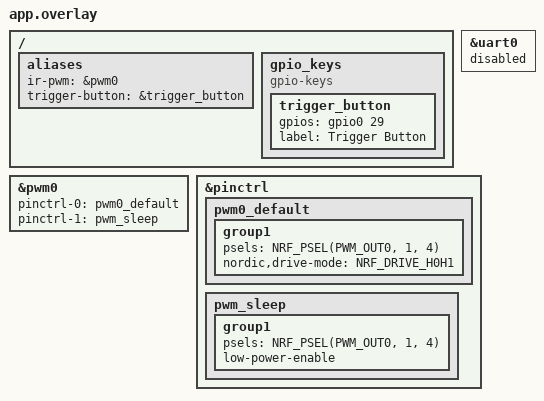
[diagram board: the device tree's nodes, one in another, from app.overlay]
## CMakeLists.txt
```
# SPDX-License-Identifier: Apache-2.0
cmake_minimum_required(VERSION 3.20.0)

set(DTC_OVERLAY_FILE app.overlay)

find_package(Zephyr REQUIRED HINTS $ENV{ZEPHYR_BASE})
project(emitter)

add_subdirectory(../common common)

target_sources(app PRIVATE
    src/main.c
    src/ble_phone.c
    src/ble_vest.c
    src/game_state.c
    src/mesh.c
)

target_link_libraries(app PUBLIC common)
target_include_directories(app PRIVATE src)
```

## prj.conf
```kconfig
CONFIG_NEWLIB_LIBC=y

# --- Stack and Heap ---
CONFIG_MAIN_STACK_SIZE=4096
CONFIG_SYSTEM_WORKQUEUE_STACK_SIZE=4096

# --- Logging ---
CONFIG_LOG=y
CONFIG_LOG_DEFAULT_LEVEL=3
CONFIG_USE_SEGGER_RTT=y
CONFIG_LOG_BACKEND_RTT=y

# --- Bluetooth Low Energy ---
CONFIG_BT=y
CONFIG_BT_PERIPHERAL=y
CONFIG_BT_CENTRAL=y
CONFIG_BT_GATT_CLIENT=y
CONFIG_BT_DEVICE_NAME_DYNAMIC=y
CONFIG_BT_DEVICE_NAME="LT-E-0000"
CONFIG_BT_MAX_CONN=3

# --- ATT MTU ---
# The phone's CMD_BROADCAST_GAME_CFG payload (game header + teams + roster +
# emitter config + boundary) is ~45-200 bytes. The default 23-byte ATT MTU caps
# a single write at 20 bytes, which would force iOS into an ATT Long Write that
# this server rejects (CONFIG_BT_ATT_PREPARE_COUNT defaults to 0), so the write
# silently fails and the game never starts. Bump the MTU so the whole config
# lands in one write. DLE max lets it travel without LL fragmentation.
CONFIG_BT_L2CAP_TX_MTU=247
CONFIG_BT_BUF_ACL_TX_SIZE=251
CONFIG_BT_BUF_ACL_RX_SIZE=251
CONFIG_BT_CTLR_DATA_LENGTH_MAX=251

# --- Hardware Drivers ---
CONFIG_GPIO=y
CONFIG_PWM=y

# --- Settings Subsystem (NVS) ---
CONFIG_SETTINGS=y
CONFIG_FLASH=y
CONFIG_FLASH_PAGE_LAYOUT=y
CONFIG_FLASH_MAP=y
CONFIG_NVS=y
CONFIG_SETTINGS_NVS=y

# --- Coded PHY & Extended Adv ---
CONFIG_BT_OBSERVER=y
CONFIG_BT_BROADCASTER=y
CONFIG_BT_EXT_ADV=y
CONFIG_BT_EXT_ADV_MAX_ADV_SET=3
CONFIG_BT_CTLR_ADV_EXT=y
CONFIG_BT_CTLR_PHY_CODED=y
CONFIG_BT_USER_PHY_UPDATE=y

# --- TX Power (max for mesh range) ---
CONFIG_BT_CTLR_TX_PWR_PLUS_8=y

# --- Entropy for random numbers ---
CONFIG_ENTROPY_GENERATOR=y
CONFIG_TEST_RANDOM_GENERATOR=n
CONFIG_BT_GATT_AUTO_DISCOVER_CCC=y
```

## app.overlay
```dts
/ {
    aliases {
        ir-pwm = &pwm0;
        trigger-button = &trigger_button;
    };

    gpio_keys {
        compatible = "gpio-keys";
        trigger_button: trigger_button {
            /* Trigger switch is on P0.29, normally-closed, wired between
             * pin and GND. With the NC closed at idle, the switch shorts
             * the pin to GND (overrides the internal pull-up). Pressing
             * the trigger opens the NC contact, the pull-up takes the
             * pin HIGH, which reads as "active" per GPIO_ACTIVE_HIGH.
             *
             * Symptom that pinpointed this wiring: with ACTIVE_HIGH +
             * PULL_DOWN, no fires happen because pressing doesn't pull
             * the pin HIGH (NC opens, but pull-down still wins). With
             * ACTIVE_LOW + PULL_UP, fires happen at idle because the
             * NC short reads as "active". The combo here is the only
             * one that lines up.
             *
             * The 20 ms ISR debounce in trigger_pressed_cb handles the
             * release-bounce that previously caused double-fires under
             * this same polarity + pull combo.
             */
            gpios = <&gpio0 29 (GPIO_ACTIVE_HIGH | GPIO_PULL_UP)>;
            label = "Trigger Button";
        };
    };
};

/*
 * Disable uart0 to free up its pins (like P0.20) for other uses.
 * This is safe because we are using the USB serial backend for logs.
 */
&uart0 {
    status = "disabled";
};

&pwm0 {
    status = "okay";
    pinctrl-0 = <&pwm0_default>;
    pinctrl-1 = <&pwm_sleep>;
    pinctrl-names = "default", "sleep";
};

&pinctrl {
    pwm0_default: pwm0_default {
        group1 {
            /* IR LED on P1.04. H0H1 high drive (~5 mA, vs ~0.5 mA standard)
             * so the pin can source enough current for a direct-driven IR LED
             * or hard-saturate the switching transistor.
             */
            psels = <NRF_PSEL(PWM_OUT0, 1, 4)>;
            nordic,drive-mode = <NRF_DRIVE_H0H1>;
        };
    };

    pwm_sleep: pwm_sleep {
        group1 {
            psels = <NRF_PSEL(PWM_OUT0, 1, 4)>;
            low-power-enable;
        };
    };
};
```

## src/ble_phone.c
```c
#include "ble_phone.h"
#include "protocol.h"
#include <zephyr/bluetooth/gatt.h>
#include <zephyr/bluetooth/uuid.h>
#include <zephyr/logging/log.h>
#include <stdarg.h>
#include <stdio.h>
#include <string.h>

LOG_MODULE_REGISTER(ble_phone, LOG_LEVEL_INF);

/* Emitter Service: e4b50001-c812-4d2b-b6d0-456789abcdef */
#define BT_UUID_EMITTER_SVC_VAL BT_UUID_128_ENCODE(0xe4b50001, 0xc812, 0x4d2b, 0xb6d0, 0x456789abcdef)
#define BT_UUID_EMITTER_RX_VAL  BT_UUID_128_ENCODE(0xe4b50002, 0xc812, 0x4d2b, 0xb6d0, 0x456789abcdef)
#define BT_UUID_EMITTER_TX_VAL  BT_UUID_128_ENCODE(0xe4b50003, 0xc812, 0x4d2b, 0xb6d0, 0x456789abcdef)

#define BT_UUID_EMITTER_SVC BT_UUID_DECLARE_128(BT_UUID_EMITTER_SVC_VAL)
#define BT_UUID_EMITTER_RX  BT_UUID_DECLARE_128(BT_UUID_EMITTER_RX_VAL)
#define BT_UUID_EMITTER_TX  BT_UUID_DECLARE_128(BT_UUID_EMITTER_TX_VAL)

static ble_phone_rx_cb_t app_rx_cb;

/* Tracked separately from the caller's `phone_conn` so the logging path
 * doesn't have to thread a connection pointer through every module.
 * Set/cleared by main.c via ble_phone_log_set_conn in the BLE
 * connected/disconnected callbacks.
 */
static struct bt_conn *log_conn;

static ssize_t on_rx_write(struct bt_conn *conn, const struct bt_gatt_attr *attr,
                           const void *buf, uint16_t len, uint16_t offset, uint8_t flags)
{
    if (len > 0 && app_rx_cb) {
        app_rx_cb((const uint8_t *)buf, len);
    }
    return len;
}

BT_GATT_SERVICE_DEFINE(emitter_phone_svc,
    BT_GATT_PRIMARY_SERVICE(BT_UUID_EMITTER_SVC),
    BT_GATT_CHARACTERISTIC(BT_UUID_EMITTER_TX,
                           BT_GATT_CHRC_NOTIFY,
                           BT_GATT_PERM_NONE,
                           NULL, NULL, NULL),
    BT_GATT_CCC(NULL, BT_GATT_PERM_READ | BT_GATT_PERM_WRITE),
    BT_GATT_CHARACTERISTIC(BT_UUID_EMITTER_RX,
                           BT_GATT_CHRC_WRITE | BT_GATT_CHRC_WRITE_WITHOUT_RESP,
                           BT_GATT_PERM_WRITE,
                           NULL, on_rx_write, NULL),
);

void ble_phone_init(ble_phone_rx_cb_t rx_cb)
{
    app_rx_cb = rx_cb;
}

void ble_phone_notify(struct bt_conn *conn, const uint8_t *data, uint16_t len)
{
    if (!conn) {
        return;
    }
    int err = bt_gatt_notify(conn, &emitter_phone_svc.attrs[2], data, len);
    if (err) {
        LOG_WRN("Phone notify failed (err %d)", err);
    }
}

void ble_phone_log_set_conn(struct bt_conn *conn)
{
    log_conn = conn;
}

void ble_phone_log(uint8_t severity, const char *fmt, ...)
{
    if (!log_conn) {
        return;
    }

    /* notify_buf layout: [opcode][severity][text...] — text is NOT
     * NUL-terminated; the receiver uses the BLE notify length to know
     * where it ends.
     */
    uint8_t notify_buf[152];
    notify_buf[0] = RSP_LOG;
    notify_buf[1] = severity;

    va_list ap;
    va_start(ap, fmt);
    int n = vsnprintf((char *)&notify_buf[2], sizeof(notify_buf) - 2, fmt, ap);
    va_end(ap);

    if (n < 0) {
        return;
    }
    size_t text_len = (size_t)n;
    if (text_len > sizeof(notify_buf) - 2) {
        text_len = sizeof(notify_buf) - 2;  /* vsnprintf truncated */
    }
    size_t total = 2 + text_len;

    /* Notification payload is bounded by the current ATT MTU minus the
     * 3-byte ATT_HANDLE_VALUE_NTF header. iOS auto-negotiates ~185 byte
     * MTU shortly after connect but the exchange takes a moment — if a
     * log line fires before MTU is up, bt_gatt_notify returns -EMSGSIZE
     * and the entire line is silently lost. Trim to whatever MTU
     * actually is right now (worst case 23 → 20 byte payloads).
     */
    uint16_t mtu = bt_gatt_get_mtu(log_conn);
    if (mtu < 5) {
        return;  /* shouldn't happen — bail rather than write a negative size */
    }
    size_t max_payload = (size_t)mtu - 3;
    if (total > max_payload) {
        total = max_payload;
    }

    /* bt_gatt_notify is non-blocking and returns -ENOMEM if the host's
     * TX queue is full; we drop the log line in that case rather than
     * blocking the caller (which may be on the BT host thread itself).
     * Log failures so they're at least visible in RTT when attached.
     */
    int err = bt_gatt_notify(log_conn, &emitter_phone_svc.attrs[2],
                             notify_buf, total);
    if (err) {
        LOG_WRN("RSP_LOG notify failed (err %d, mtu=%u, total=%u)",
                err, mtu, (unsigned)total);
    }
}
```

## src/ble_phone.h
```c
#ifndef BLE_PHONE_H
#define BLE_PHONE_H

#include <zephyr/bluetooth/bluetooth.h>
#include <zephyr/bluetooth/conn.h>
#include <zephyr/logging/log.h>
#include <stdint.h>

typedef void (*ble_phone_rx_cb_t)(const uint8_t *data, uint16_t len);

void ble_phone_init(ble_phone_rx_cb_t rx_cb);
void ble_phone_notify(struct bt_conn *conn, const uint8_t *data, uint16_t len);

/* ===== Log relay to phone =====
 *
 * Forwards short log lines to the phone over the existing emitter
 * connection as RSP_LOG notifications. Useful when the emitter is on
 * battery and SWD isn't accessible: the iOS app's log viewer surfaces
 * what the RTT terminal would normally show.
 *
 * Severity values: 0=DBG 1=INF 2=WRN 3=ERR. Lines longer than the
 * negotiated ATT MTU are truncated (~150 bytes typically).
 *
 * Use PLOG_INF/PLOG_WRN/PLOG_ERR macros: they log to the Zephyr backend
 * (RTT) AND relay to the phone in one call, so there's a single source
 * of truth for the message text.
 */
void ble_phone_log_set_conn(struct bt_conn *conn);
void ble_phone_log(uint8_t severity, const char *fmt, ...);

#define PLOG_INF(fmt, ...) do { \
    LOG_INF(fmt, ##__VA_ARGS__); \
    ble_phone_log(1, fmt, ##__VA_ARGS__); \
} while (0)

#define PLOG_WRN(fmt, ...) do { \
    LOG_WRN(fmt, ##__VA_ARGS__); \
    ble_phone_log(2, fmt, ##__VA_ARGS__); \
} while (0)

#define PLOG_ERR(fmt, ...) do { \
    LOG_ERR(fmt, ##__VA_ARGS__); \
    ble_phone_log(3, fmt, ##__VA_ARGS__); \
} while (0)

#endif
```

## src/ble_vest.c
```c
#include "ble_vest.h"
#include "ble_phone.h"
#include "protocol.h"
#include "mesh.h"
#include <zephyr/kernel.h>
#include <zephyr/bluetooth/gatt.h>
#include <zephyr/bluetooth/uuid.h>
#include <zephyr/bluetooth/hci.h>
#include <zephyr/sys/byteorder.h>
#include <zephyr/logging/log.h>
#include <string.h>

LOG_MODULE_REGISTER(ble_vest, LOG_LEVEL_INF);

/* Vest Service UUIDs */
#define BT_UUID_VEST_SVC_VAL    BT_UUID_128_ENCODE(0xa7d80001, 0x1234, 0x5678, 0xabcd, 0x0123456789ab)
#define BT_UUID_VEST_HIT_TX_VAL BT_UUID_128_ENCODE(0xa7d80002, 0x1234, 0x5678, 0xabcd, 0x0123456789ab)
#define BT_UUID_VEST_CMD_RX_VAL BT_UUID_128_ENCODE(0xa7d80003, 0x1234, 0x5678, 0xabcd, 0x0123456789ab)

static struct bt_uuid_128 vest_svc_uuid    = BT_UUID_INIT_128(BT_UUID_VEST_SVC_VAL);
static struct bt_uuid_128 vest_hit_tx_uuid = BT_UUID_INIT_128(BT_UUID_VEST_HIT_TX_VAL);
static struct bt_uuid_128 vest_cmd_rx_uuid = BT_UUID_INIT_128(BT_UUID_VEST_CMD_RX_VAL);

/* State */
static struct bt_conn *vest_conn;
static uint16_t cmd_rx_handle;
static ble_vest_hit_cb_t hit_cb;
static ble_vest_connected_cb_t connected_cb;
static ble_vest_disconnected_cb_t disconnected_cb;
static ble_vest_ready_cb_t ready_cb;
static uint8_t vest_mac[6];
static bool has_vest_mac;

/* GATT discovery state machine */
enum discover_stage {
    DISC_SERVICE,
    DISC_CHAR,
    DISC_CCC,
    DISC_DONE,
};
static enum discover_stage disc_stage;
static struct bt_gatt_discover_params discover_params;
static struct bt_gatt_subscribe_params subscribe_params;
static uint16_t svc_start_handle;
static uint16_t svc_end_handle;
static uint16_t hit_tx_value_handle;

/* Deferred firing of ready_cb — runs on system workqueue so the callback
 * (which typically issues another GATT write) doesn't execute inside the
 * BT host thread's discovery callback.
 */
static struct k_work ready_cb_work;

static void ready_cb_handler(struct k_work *work)
{
    if (ready_cb) {
        ready_cb();
    }
}

/* Forward declarations */
static uint8_t gatt_discover_cb(struct bt_conn *conn,
                                const struct bt_gatt_attr *attr,
                                struct bt_gatt_discover_params *params);

static uint8_t hit_notify_cb(struct bt_conn *conn,
                             struct bt_gatt_subscribe_params *params,
                             const void *data, uint16_t length)
{
    if (!data || length < VEST_HIT_PAYLOAD_SIZE) {
        return BT_GATT_ITER_CONTINUE;
    }

    const uint8_t *d = data;
    uint16_t packet_id = sys_get_le16(&d[0]);
    uint8_t shooter_id = d[2];
    uint8_t weapon_id  = d[3];
    uint8_t team_id    = d[4];

    PLOG_INF("Vest hit RX: pkt=0x%04x shooter=%d weapon=%d team=%d",
             packet_id, shooter_id, weapon_id, team_id);

    if (hit_cb) {
        hit_cb(packet_id, shooter_id, weapon_id, team_id);
    }
    return BT_GATT_ITER_CONTINUE;
}

static void start_gatt_discovery(struct bt_conn *conn)
{
    disc_stage = DISC_SERVICE;
    discover_params.uuid = &vest_svc_uuid.uuid;
    discover_params.func = gatt_discover_cb;
    discover_params.start_handle = BT_ATT_FIRST_ATTRIBUTE_HANDLE;
    discover_params.end_handle = BT_ATT_LAST_ATTRIBUTE_HANDLE;
    discover_params.type = BT_GATT_DISCOVER_PRIMARY;

    int err = bt_gatt_discover(conn, &discover_params);
    if (err) {
        LOG_ERR("GATT discovery start failed (err %d)", err);
    }
}

static uint8_t gatt_discover_cb(struct bt_conn *conn,
                                const struct bt_gatt_attr *attr,
                                struct bt_gatt_discover_params *params)
{
    if (!attr) {
        if (disc_stage == DISC_SERVICE) {
            PLOG_ERR("Vest service not found");
        }
        return BT_GATT_ITER_STOP;
    }

    switch (disc_stage) {
    case DISC_SERVICE: {
        struct bt_gatt_service_val *svc = attr->user_data;
        svc_start_handle = attr->handle + 1;
        svc_end_handle = svc->end_handle;
        LOG_INF("Vest service found: handles %d-%d", svc_start_handle, svc_end_handle);

        disc_stage = DISC_CHAR;
        discover_params.uuid = NULL;
        discover_params.start_handle = svc_start_handle;
        discover_params.end_handle = svc_end_handle;
        discover_params.type = BT_GATT_DISCOVER_CHARACTERISTIC;

        int err = bt_gatt_discover(conn, &discover_params);
        if (err) {
            LOG_ERR("Char discovery failed (err %d)", err);
        }
        return BT_GATT_ITER_STOP;
    }

    case DISC_CHAR: {
        struct bt_gatt_chrc *chrc = attr->user_data;
        if (!bt_uuid_cmp(chrc->uuid, &vest_hit_tx_uuid.uuid)) {
            hit_tx_value_handle = chrc->value_handle;
            LOG_INF("Hit TX char found: handle %d", hit_tx_value_handle);
        } else if (!bt_uuid_cmp(chrc->uuid, &vest_cmd_rx_uuid.uuid)) {
            cmd_rx_handle = chrc->value_handle;
            LOG_INF("Cmd RX char found: handle %d", cmd_rx_handle);
        }

        if (hit_tx_value_handle && cmd_rx_handle) {
            disc_stage = DISC_CCC;
            subscribe_params.notify = hit_notify_cb;
            subscribe_params.value_handle = hit_tx_value_handle;
            subscribe_params.ccc_handle = 0;
            subscribe_params.end_handle = svc_end_handle;
            subscribe_params.disc_params = &discover_params;
            subscribe_params.value = BT_GATT_CCC_NOTIFY;

            int err = bt_gatt_subscribe(conn, &subscribe_params);
            if (err && err != -EALREADY) {
                PLOG_ERR("Subscribe failed (err %d)", err);
            } else {
                PLOG_INF("Subscribed to vest Hit TX");
                disc_stage = DISC_DONE;
                k_work_submit(&ready_cb_work);
            }
            return BT_GATT_ITER_STOP;
        }
        return BT_GATT_ITER_CONTINUE;
    }

    default:
        return BT_GATT_ITER_STOP;
    }
}

static void vest_conn_connected(struct bt_conn *conn, uint8_t err)
{
    /* Bail early if this isn't our pending vest connection — the connected
     * callback also fires for phone connections, and an err here for the
     * phone must not wipe out a separately-tracked vest connection.
     */
    if (conn != vest_conn) {
        return;
    }

    if (err) {
        PLOG_ERR("Vest connection failed (err %d)", err);
        bt_conn_unref(vest_conn);
        vest_conn = NULL;
        mesh_start_scanner();
        return;
    }

    const bt_addr_le_t *addr = bt_conn_get_dst(conn);
    if (!addr) {
        return;
    }

    char addr_str[BT_ADDR_LE_STR_LEN];
    bt_addr_le_to_str(addr, addr_str, sizeof(addr_str));
    LOG_INF("Vest connected: %s", addr_str);

    memcpy(vest_mac, addr->a.val, 6);
    has_vest_mac = true;

    cmd_rx_handle = 0;
    hit_tx_value_handle = 0;
    start_gatt_discovery(conn);

    /* Deliberately do NOT restart the mesh scanner here. Scanning during
     * GATT discovery time-slices the radio against both the new vest
     * connection's traffic and the existing phone connection — on a
     * Pro Micro that's enough to make supervision packets to the phone
     * slip and iOS drops the link mid-pairing. The scanner gets
     * restarted from on_vest_gatt_ready once discovery has completed.
     */

    if (connected_cb) {
        connected_cb(vest_mac);
    }
}

static void vest_conn_disconnected(struct bt_conn *conn, uint8_t reason)
{
    if (conn == vest_conn) {
        LOG_INF("Vest disconnected (reason %d)", reason);
        bt_conn_unref(vest_conn);
        vest_conn = NULL;
        cmd_rx_handle = 0;
        hit_tx_value_handle = 0;

        mesh_start_scanner();

        if (disconnected_cb) {
            disconnected_cb(reason);
        }
    }
}

BT_CONN_CB_DEFINE(vest_conn_cbs) = {
    .connected = vest_conn_connected,
    .disconnected = vest_conn_disconnected,
};

/* ===== Vest Scan (1M PHY for vest pairing/reconnect) ===== */

void ble_vest_stop_scan(void)
{
    int err = bt_le_scan_stop();
    if (err && err != -EALREADY) {
        LOG_WRN("Stop scan failed (err %d)", err);
    }
}

static void vest_scan_connect(const bt_addr_le_t *addr)
{
    if (vest_conn) {
        mesh_start_scanner();
        return;
    }

    struct bt_le_conn_param conn_param = BT_LE_CONN_PARAM_INIT(
        BT_GAP_INIT_CONN_INT_MIN, BT_GAP_INIT_CONN_INT_MAX, 0, 400);

    struct bt_conn *conn;
    int err = bt_conn_le_create(addr, BT_CONN_LE_CREATE_CONN,
                                &conn_param, &conn);
    if (err) {
        LOG_ERR("Vest connect failed (err %d)", err);
        mesh_start_scanner();
        return;
    }
    vest_conn = conn;
    LOG_INF("Connecting to vest...");
}

void ble_vest_init(ble_vest_hit_cb_t hit_callback,
                   ble_vest_connected_cb_t conn_cb,
                   ble_vest_disconnected_cb_t disc_cb,
                   ble_vest_ready_cb_t rdy_cb)
{
    hit_cb = hit_callback;
    connected_cb = conn_cb;
    disconnected_cb = disc_cb;
    ready_cb = rdy_cb;
    k_work_init(&ready_cb_work, ready_cb_handler);
}

void ble_vest_on_scan_result(const bt_addr_le_t *addr, int8_t rssi,
                             struct net_buf_simple *buf)
{
    if (vest_conn) {
        return;
    }

    /* Look for vest name prefix "LT-V-" in the advertisement */
    if (buf->len >= 2) {
        uint8_t *d = buf->data;
        uint16_t pos = 0;
        while (pos + 1 < buf->len) {
            uint8_t ad_len = d[pos];
            if (ad_len == 0 || pos + 1 + ad_len > buf->len) {
                break;
            }
            uint8_t ad_type = d[pos + 1];
            if ((ad_type == BT_DATA_NAME_COMPLETE || ad_type == BT_DATA_NAME_SHORTENED) &&
                ad_len >= 6) {
                const char *name = (const char *)&d[pos + 2];
                if (name[0] == 'L' && name[1] == 'T' && name[2] == '-' &&
                    name[3] == 'V' && name[4] == '-') {
                    LOG_INF("Found vest: RSSI=%d", rssi);
                    ble_vest_stop_scan();
                    vest_scan_connect(addr);
                    return;
                }
            }
            pos += ad_len + 1;
        }
    }
}

/* ===== Commands to Vest ===== */

static int vest_write(const uint8_t *data, uint16_t len)
{
    if (!vest_conn || cmd_rx_handle == 0) {
        return -ENOTCONN;
    }
    return bt_gatt_write_without_response(vest_conn, cmd_rx_handle, data, len, false);
}

int ble_vest_send_hit_ack(uint16_t packet_id)
{
    uint8_t buf[3];
    buf[0] = VEST_CMD_HIT_ACK;
    sys_put_le16(packet_id, &buf[1]);
    return vest_write(buf, 3);
}

int ble_vest_send_friendly_list(const uint8_t *player_ids, uint8_t count)
{
    uint8_t buf[2 + MAX_PLAYERS];
    buf[0] = VEST_CMD_FRIENDLY_LIST;
    buf[1] = count;
    if (count > MAX_PLAYERS) count = MAX_PLAYERS;
    memcpy(&buf[2], player_ids, count);
    return vest_write(buf, 2 + count);
}

int ble_vest_send_death(void)
{
    uint8_t buf[1] = { VEST_CMD_DEATH };
    return vest_write(buf, 1);
}

int ble_vest_send_respawn(void)
{
    uint8_t buf[1] = { VEST_CMD_RESPAWN };
    return vest_write(buf, 1);
}

int ble_vest_send_friendly_fire(uint8_t enabled)
{
    uint8_t buf[2] = { VEST_CMD_FRIENDLY_FIRE, enabled };
    return vest_write(buf, 2);
}

int ble_vest_send_unpair(void)
{
    uint8_t buf[1] = { VEST_CMD_UNPAIR };
    return vest_write(buf, 1);
}

bool ble_vest_is_connected(void)
{
    return vest_conn != NULL && cmd_rx_handle != 0;
}

bool ble_vest_link_up(void)
{
    return vest_conn != NULL;
}

void ble_vest_disconnect(void)
{
    if (vest_conn) {
        bt_conn_disconnect(vest_conn, BT_HCI_ERR_REMOTE_USER_TERM_CONN);
    }
}

bool ble_vest_get_active_mac(uint8_t mac_out[6])
{
    if (!vest_conn || !has_vest_mac) {
        return false;
    }
    memcpy(mac_out, vest_mac, 6);
    return true;
}
```

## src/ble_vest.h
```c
#ifndef BLE_VEST_H
#define BLE_VEST_H

#include <zephyr/bluetooth/bluetooth.h>
#include <zephyr/bluetooth/conn.h>
#include <zephyr/net_buf.h>
#include <stdint.h>
#include <stdbool.h>

typedef void (*ble_vest_hit_cb_t)(uint16_t packet_id, uint8_t shooter_id,
                                  uint8_t weapon_id, uint8_t team_id);
typedef void (*ble_vest_connected_cb_t)(const uint8_t *vest_mac);
typedef void (*ble_vest_disconnected_cb_t)(uint8_t reason);
/* Fired once GATT discovery + subscription have completed and the link
 * is fully usable. Used by the emitter to notify the phone via
 * RSP_VEST_PAIRED at the right moment — after the connection is
 * actually ready to carry commands, not the instant BLE links up.
 */
typedef void (*ble_vest_ready_cb_t)(void);

void ble_vest_init(ble_vest_hit_cb_t hit_cb,
                   ble_vest_connected_cb_t connected_cb,
                   ble_vest_disconnected_cb_t disconnected_cb,
                   ble_vest_ready_cb_t ready_cb);

/* Called from main scan callback when a 1M advertisement is received */
void ble_vest_on_scan_result(const bt_addr_le_t *addr, int8_t rssi,
                             struct net_buf_simple *buf);

void ble_vest_stop_scan(void);

int ble_vest_send_hit_ack(uint16_t packet_id);
int ble_vest_send_friendly_list(const uint8_t *player_ids, uint8_t count);
int ble_vest_send_death(void);
int ble_vest_send_respawn(void);
int ble_vest_send_friendly_fire(uint8_t enabled);
int ble_vest_send_unpair(void);

bool ble_vest_is_connected(void);
/* True as soon as the BLE link to the vest is established, even before
 * GATT discovery completes. Used by the pairing-IR transmitter to stop
 * firing once we have a connection — continuing to fire from the
 * cooperative IR workqueue starves the system workqueue / BT host
 * thread and prevents PAIR_CONFIRM from going out.
 */
bool ble_vest_link_up(void);
void ble_vest_disconnect(void);

/* If a vest is currently connected at BLE level, copy its 6-byte MAC into
 * mac_out and return true.
 */
bool ble_vest_get_active_mac(uint8_t mac_out[6]);

#endif
```

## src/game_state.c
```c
#include "game_state.h"
#include <zephyr/kernel.h>
#include <zephyr/logging/log.h>

LOG_MODULE_REGISTER(game_state, LOG_LEVEL_INF);

static struct emitter_config cfg;
static uint8_t  health;
static uint16_t mag_current;
static uint16_t reserve_current;
static bool     alive;
static bool     reloading;
static int64_t  last_shot_ms;
static uint16_t kills;
static uint16_t deaths;

void game_state_init(void)
{
    memset(&cfg, 0, sizeof(cfg));
    health = 0;
    mag_current = 0;
    reserve_current = 0;
    alive = false;
    reloading = false;
    last_shot_ms = 0;
    kills = 0;
    deaths = 0;
}

void game_state_set_config(const struct emitter_config *new_cfg)
{
    cfg = *new_cfg;
    LOG_INF("Config set: dmg=%d mag=%d fire_rate=%dms reload=%dms hp=%d ff=%d",
            cfg.damage, cfg.mag_size, cfg.fire_rate_ms,
            cfg.reload_speed_ms, cfg.max_health, cfg.friendly_fire);
}

const struct emitter_config *game_state_get_config(void)
{
    return &cfg;
}

void game_state_start_game(void)
{
    health = cfg.max_health;
    uint16_t starting_mag = (cfg.initial_total_ammo > cfg.mag_size)
                            ? cfg.mag_size : cfg.initial_total_ammo;
    mag_current = starting_mag;
    reserve_current = cfg.initial_total_ammo - starting_mag;
    alive = true;
    reloading = false;
    last_shot_ms = 0;
    kills = 0;
    deaths = 0;
    LOG_INF("Game started: HP=%d Mag=%d Reserve=%d", health, mag_current, reserve_current);
}

bool game_state_try_fire(int64_t now_ms)
{
    if (!alive || reloading || mag_current == 0) {
        return false;
    }
    if (last_shot_ms > 0 && (now_ms - last_shot_ms) < cfg.fire_rate_ms) {
        return false;
    }
    mag_current--;
    last_shot_ms = now_ms;
    return true;
}

bool game_state_apply_hit(uint8_t damage)
{
    if (!alive) {
        return false;
    }
    if (damage >= health) {
        health = 0;
        alive = false;
        deaths++;
        LOG_INF("DEATH! kills=%d deaths=%d", kills, deaths);
        return true;
    }
    health -= damage;
    LOG_INF("Hit taken: HP=%d", health);
    return false;
}

bool game_state_start_reload(void)
{
    if (reloading) {
        return false;
    }
    if (mag_current == cfg.mag_size) {
        return false;
    }
    if (reserve_current == 0 && mag_current > 0) {
        return false;
    }
    reloading = true;
    LOG_INF("Reloading... (%dms)", cfg.reload_speed_ms);
    return true;
}

void game_state_complete_reload(void)
{
    uint16_t needed = cfg.mag_size - mag_current;
    uint16_t transfer = (reserve_current >= needed) ? needed : reserve_current;
    mag_current += transfer;
    reserve_current -= transfer;
    reloading = false;
    LOG_INF("Reload done: Mag=%d Reserve=%d", mag_current, reserve_current);
}

void game_state_respawn(void)
{
    health = cfg.max_health;
    uint16_t starting_mag = (cfg.initial_total_ammo > cfg.mag_size)
                            ? cfg.mag_size : cfg.initial_total_ammo;
    mag_current = starting_mag;
    reserve_current = cfg.initial_total_ammo - starting_mag;
    alive = true;
    reloading = false;
    LOG_INF("Respawned: HP=%d Mag=%d Reserve=%d", health, mag_current, reserve_current);
}

void game_state_add_ammo(uint16_t amount)
{
    reserve_current += amount;
    LOG_INF("Ammo added: +%d, Reserve=%d", amount, reserve_current);
}

void game_state_add_kill(void)
{
    kills++;
}

uint8_t  game_state_get_health(void)       { return health; }
uint16_t game_state_get_mag_ammo(void)     { return mag_current; }
uint16_t game_state_get_reserve_ammo(void) { return reserve_current; }
bool     game_state_is_alive(void)         { return alive; }
bool     game_state_is_reloading(void)     { return reloading; }
uint16_t game_state_get_kills(void)        { return kills; }
uint16_t game_state_get_deaths(void)       { return deaths; }
```

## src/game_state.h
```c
#ifndef GAME_STATE_H
#define GAME_STATE_H

#include "protocol.h"
#include <stdbool.h>

void game_state_init(void);
void game_state_set_config(const struct emitter_config *cfg);
const struct emitter_config *game_state_get_config(void);

void game_state_start_game(void);
bool game_state_try_fire(int64_t now_ms);
bool game_state_apply_hit(uint8_t damage);
bool game_state_start_reload(void);
void game_state_complete_reload(void);
void game_state_respawn(void);
void game_state_add_ammo(uint16_t amount);
void game_state_add_kill(void);

uint8_t  game_state_get_health(void);
uint16_t game_state_get_mag_ammo(void);
uint16_t game_state_get_reserve_ammo(void);
bool     game_state_is_alive(void);
bool     game_state_is_reloading(void);
uint16_t game_state_get_kills(void);
uint16_t game_state_get_deaths(void);

#endif
```

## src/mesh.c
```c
#include "mesh.h"
#include "ble_phone.h"
#include <zephyr/kernel.h>
#include <zephyr/random/random.h>
#include <zephyr/sys/byteorder.h>
#include <zephyr/logging/log.h>
#include <stdlib.h>
#include <string.h>

LOG_MODULE_REGISTER(mesh, LOG_LEVEL_INF);

/* ===== State ===== */
static uint8_t local_player_id;
static uint8_t local_team_id;
static struct bt_conn *phone_conn;
static uint16_t seq_counter;
static mesh_game_start_cb_t game_start_cb;

/* ===== Coded PHY Advertising Set ===== */
static struct bt_le_ext_adv *coded_adv_set;
static struct k_work_delayable stop_adv_work;
static struct k_work tx_pump_work;
static atomic_t is_broadcasting = ATOMIC_INIT(0);

/* ===== TX Queue (multi-context callers serialized into one BLE op stream) =====
 * Callers come from system workqueue (periodic timers), BT host thread
 * (on_vest_hit -> mesh_broadcast_hit_event), and the GATT write handler.
 * Without queueing, overlapping broadcasts fail with -EBUSY and are lost.
 */
#define MESH_TX_QUEUE_SIZE 4
struct mesh_tx_slot {
    uint8_t  buf[256];
    uint16_t len;
};
static struct mesh_tx_slot tx_queue[MESH_TX_QUEUE_SIZE];
static uint8_t tx_q_head;
static uint8_t tx_q_tail;
static uint8_t tx_q_count;
K_MUTEX_DEFINE(tx_q_mutex);

/* ===== Dedup Ring Buffer ===== */
struct dedup_entry {
    uint8_t  origin_id;
    uint16_t seq_num;
    bool     used;
};
static struct dedup_entry dedup_buf[MESH_DEDUP_SIZE];
static uint8_t dedup_idx;

/* ===== Scan ===== */
static struct bt_le_scan_param coded_scan_param = {
    .type     = BT_LE_SCAN_TYPE_PASSIVE,
    .options  = BT_LE_SCAN_OPT_CODED,
    .interval = 0x00A0,
    .window   = 0x00A0,
};

/* ===== Repeat broadcast state ===== */
static uint8_t repeat_buf[256];
static uint16_t repeat_len;
static uint8_t repeat_remaining;
static struct k_work_delayable repeat_work;

/* ===== Relay work (avoids blocking BT thread) ===== */
static uint8_t relay_buf_pending[256];
static uint16_t relay_len_pending;
static struct k_work_delayable relay_work;

/* ===== Internal ===== */

static bool dedup_check_and_insert(uint8_t origin_id, uint16_t seq_num)
{
    for (int i = 0; i < MESH_DEDUP_SIZE; i++) {
        if (dedup_buf[i].used &&
            dedup_buf[i].origin_id == origin_id &&
            dedup_buf[i].seq_num == seq_num) {
            return true;
        }
    }
    dedup_buf[dedup_idx].origin_id = origin_id;
    dedup_buf[dedup_idx].seq_num = seq_num;
    dedup_buf[dedup_idx].used = true;
    dedup_idx = (dedup_idx + 1) % MESH_DEDUP_SIZE;
    return false;
}

static bool tx_q_push(const uint8_t *data, uint16_t len)
{
    if (len == 0 || len > sizeof(tx_queue[0].buf)) {
        return false;
    }
    bool ok = false;
    k_mutex_lock(&tx_q_mutex, K_FOREVER);
    if (tx_q_count < MESH_TX_QUEUE_SIZE) {
        memcpy(tx_queue[tx_q_tail].buf, data, len);
        tx_queue[tx_q_tail].len = len;
        tx_q_tail = (tx_q_tail + 1) % MESH_TX_QUEUE_SIZE;
        tx_q_count++;
        ok = true;
    }
    k_mutex_unlock(&tx_q_mutex);
    return ok;
}

static bool tx_q_pop(uint8_t *out, uint16_t *out_len)
{
    bool ok = false;
    k_mutex_lock(&tx_q_mutex, K_FOREVER);
    if (tx_q_count > 0) {
        *out_len = tx_queue[tx_q_head].len;
        memcpy(out, tx_queue[tx_q_head].buf, *out_len);
        tx_q_head = (tx_q_head + 1) % MESH_TX_QUEUE_SIZE;
        tx_q_count--;
        ok = true;
    }
    k_mutex_unlock(&tx_q_mutex);
    return ok;
}

static void do_coded_broadcast(const uint8_t *data, uint16_t len)
{
    if (!coded_adv_set || len == 0) {
        return;
    }
    if (!tx_q_push(data, len)) {
        LOG_WRN("Mesh TX queue full, dropping %u byte broadcast", len);
        return;
    }
    if (!atomic_get(&is_broadcasting)) {
        k_work_submit(&tx_pump_work);
    }
}

static void tx_pump_handler(struct k_work *work)
{
    if (atomic_get(&is_broadcasting)) {
        return;
    }

    uint8_t buf[256];
    uint16_t len;
    if (!tx_q_pop(buf, &len)) {
        mesh_start_scanner();
        return;
    }
    if (!coded_adv_set) {
        return;
    }

    bt_le_scan_stop();

    struct bt_data ad[] = {
        BT_DATA(BT_DATA_MANUFACTURER_DATA, buf, len)
    };

    int err = bt_le_ext_adv_set_data(coded_adv_set, ad, ARRAY_SIZE(ad), NULL, 0);
    if (err) {
        LOG_ERR("Coded PHY set data failed (err %d)", err);
        mesh_start_scanner();
        k_work_submit(&tx_pump_work);
        return;
    }

    struct bt_le_ext_adv_start_param start_param = {
        .timeout = 0,
        .num_events = 1,
    };
    err = bt_le_ext_adv_start(coded_adv_set, &start_param);
    if (err) {
        LOG_ERR("Coded PHY adv start failed (err %d)", err);
        mesh_start_scanner();
        k_work_submit(&tx_pump_work);
        return;
    }

    atomic_set(&is_broadcasting, 1);
    k_work_reschedule(&stop_adv_work, K_MSEC(500));
}

static void stop_adv_handler(struct k_work *work)
{
    bt_le_ext_adv_stop(coded_adv_set);
    atomic_set(&is_broadcasting, 0);
    k_work_submit(&tx_pump_work);
}

static void repeat_work_handler(struct k_work *work)
{
    if (repeat_remaining > 0) {
        repeat_remaining--;
        do_coded_broadcast(repeat_buf, repeat_len);
        if (repeat_remaining > 0) {
            k_work_reschedule(&repeat_work, K_MSEC(200));
        }
    }
}

static uint16_t next_seq(void)
{
    return seq_counter++;
}

static uint16_t build_mesh_packet(uint8_t *buf, size_t buf_size,
                                  uint8_t mesh_type, const uint8_t *payload,
                                  uint8_t payload_len)
{
    if (MESH_HEADER_SIZE + payload_len > buf_size) {
        return 0;
    }
    struct mesh_header *hdr = (struct mesh_header *)buf;
    hdr->mesh_type = mesh_type;
    hdr->origin_id = local_player_id;
    hdr->seq_num = sys_cpu_to_le16(next_seq());
    hdr->ttl = MESH_DEFAULT_TTL;
    hdr->payload_len = payload_len;
    if (payload_len > 0 && payload) {
        memcpy(buf + MESH_HEADER_SIZE, payload, payload_len);
    }
    return MESH_HEADER_SIZE + payload_len;
}

static void broadcast_with_repeat(uint8_t mesh_type, const uint8_t *payload,
                                  uint8_t payload_len, uint8_t repeat_count)
{
    uint8_t buf[256];
    uint16_t len = build_mesh_packet(buf, sizeof(buf), mesh_type, payload, payload_len);
    if (len == 0) {
        return;
    }
    do_coded_broadcast(buf, len);

    if (repeat_count > 1) {
        memcpy(repeat_buf, buf, len);
        repeat_len = len;
        repeat_remaining = repeat_count - 1;
        k_work_reschedule(&repeat_work, K_MSEC(200));
    }
}

static void forward_to_phone(const uint8_t *data, uint16_t len)
{
    if (!phone_conn || len == 0 || len > 254) {
        return;
    }
    uint8_t notify_buf[255];
    notify_buf[0] = 0x05;
    memcpy(&notify_buf[1], data, len);
    ble_phone_notify(phone_conn, notify_buf, len + 1);
}

static void relay_work_handler(struct k_work *work)
{
    do_coded_broadcast(relay_buf_pending, relay_len_pending);
}

static void relay_message(const uint8_t *data, uint16_t len)
{
    if (len < MESH_HEADER_SIZE || len > sizeof(relay_buf_pending)) {
        return;
    }

    memcpy(relay_buf_pending, data, len);
    relay_len_pending = len;

    struct mesh_header *hdr = (struct mesh_header *)relay_buf_pending;
    hdr->ttl = hdr->ttl - 1;

    uint32_t jitter = MESH_RELAY_JITTER_MIN +
                      (sys_rand32_get() % (MESH_RELAY_JITTER_MAX - MESH_RELAY_JITTER_MIN + 1));
    k_work_reschedule(&relay_work, K_MSEC(jitter));
}

/* ===== Public API ===== */

void mesh_init(void)
{
    k_work_init(&tx_pump_work, tx_pump_handler);
    k_work_init_delayable(&stop_adv_work, stop_adv_handler);
    k_work_init_delayable(&repeat_work, repeat_work_handler);
    k_work_init_delayable(&relay_work, relay_work_handler);
    memset(dedup_buf, 0, sizeof(dedup_buf));
    dedup_idx = 0;
    seq_counter = 0;
    tx_q_head = 0;
    tx_q_tail = 0;
    tx_q_count = 0;
}

void mesh_set_identity(uint8_t player_id, uint8_t team_id)
{
    local_player_id = player_id;
    local_team_id = team_id;
}

void mesh_set_game_start_cb(mesh_game_start_cb_t cb)
{
    game_start_cb = cb;
}

void mesh_set_phone_conn(struct bt_conn *conn)
{
    phone_conn = conn;
}

void mesh_start_scanner(void)
{
    int err = bt_le_scan_start(&coded_scan_param, NULL);
    if (err && err != -EALREADY) {
        LOG_ERR("Coded PHY scanner start failed (err %d)", err);
    }
}

void mesh_stop_scanner(void)
{
    bt_le_scan_stop();
}

void mesh_broadcast_raw(const uint8_t *data, uint16_t len)
{
    do_coded_broadcast(data, len);
}

void mesh_broadcast_lobby_announce(uint32_t lobby_code, uint8_t game_mode,
                                   const char *host_name, uint8_t player_count)
{
    /* Wire layout (matches iOS handleLobbyAnnounce):
     * lobby_code[4] + game_mode[1] + name_len[1] + name[name_len] + player_count[1]
     */
    uint8_t payload[32];
    uint8_t idx = 0;
    sys_put_le32(lobby_code, &payload[idx]); idx += 4;
    payload[idx++] = game_mode;
    uint8_t name_len = strlen(host_name);
    if (name_len > 16) name_len = 16;
    payload[idx++] = name_len;
    memcpy(&payload[idx], host_name, name_len); idx += name_len;
    payload[idx++] = player_count;

    uint8_t buf[256];
    uint16_t len = build_mesh_packet(buf, sizeof(buf), MESH_LOBBY_ANNOUNCE, payload, idx);
    if (len > 0) {
        do_coded_broadcast(buf, len);
    }
}

void mesh_broadcast_lobby_join(uint32_t lobby_code, uint8_t player_id,
                               const char *username)
{
    /* Wire layout (matches iOS handleLobbyJoin):
     * lobby_code[4] + player_id[1] + name_len[1] + name[name_len]
     */
    uint8_t payload[32];
    uint8_t idx = 0;
    sys_put_le32(lobby_code, &payload[idx]); idx += 4;
    payload[idx++] = player_id;
    uint8_t name_len = strlen(username);
    if (name_len > 16) name_len = 16;
    payload[idx++] = name_len;
    memcpy(&payload[idx], username, name_len); idx += name_len;
    broadcast_with_repeat(MESH_LOBBY_JOIN, payload, idx, 3);
}

void mesh_broadcast_lobby_state(const uint8_t *roster, uint16_t roster_len,
                                uint8_t repeat_count)
{
    /* roster is built phone-side and already has the exact MESH_LOBBY_STATE
     * payload layout (lobby_code[4] + N×[pid,tid,nameLen,name]); we just wrap
     * it in a mesh frame with our origin id + monotonic seq. */
    if (roster_len == 0 || roster_len > 250) {
        return;
    }
    broadcast_with_repeat(MESH_LOBBY_STATE, roster, (uint8_t)roster_len, repeat_count);
}

void mesh_broadcast_game_start(const uint8_t *config_data, uint16_t config_len,
                               uint8_t repeat_count)
{
    broadcast_with_repeat(MESH_GAME_START, config_data, config_len, repeat_count);
}

void mesh_broadcast_player_state(uint8_t player_id, uint8_t team_id,
                                 int32_t lat, int32_t lon,
                                 uint8_t health, uint8_t ammo_pct,
                                 uint8_t alive, uint16_t kills, uint16_t deaths)
{
    uint8_t payload[17];
    payload[0] = player_id;
    payload[1] = team_id;
    sys_put_le32((uint32_t)lat, &payload[2]);
    sys_put_le32((uint32_t)lon, &payload[6]);
    payload[10] = health;
    payload[11] = ammo_pct;
    payload[12] = alive;
    sys_put_le16(kills, &payload[13]);
    sys_put_le16(deaths, &payload[15]);

    uint8_t buf[256];
    uint16_t len = build_mesh_packet(buf, sizeof(buf), MESH_PLAYER_STATE, payload, 17);
    if (len > 0) {
        do_coded_broadcast(buf, len);
    }
}

void mesh_broadcast_hit_event(uint8_t shooter_id, uint8_t target_id,
                              uint8_t damage, uint8_t remaining_health,
                              uint8_t hit_zone)
{
    uint8_t payload[5] = { shooter_id, target_id, damage, remaining_health, hit_zone };
    uint8_t buf[256];
    uint16_t len = build_mesh_packet(buf, sizeof(buf), MESH_HIT_EVENT, payload, 5);
    if (len > 0) {
        do_coded_broadcast(buf, len);
    }
}

void mesh_broadcast_player_death(uint8_t player_id, uint8_t killer_id,
                                 uint16_t final_kills, uint16_t final_deaths,
                                 uint8_t repeat_count)
{
    uint8_t payload[6];
    payload[0] = player_id;
    payload[1] = killer_id;
    sys_put_le16(final_kills, &payload[2]);
    sys_put_le16(final_deaths, &payload[4]);
    broadcast_with_repeat(MESH_PLAYER_DEATH, payload, 6, repeat_count);
}

void mesh_broadcast_game_end(uint8_t reason, uint8_t winning_team,
                             uint8_t repeat_count)
{
    uint8_t payload[2] = { reason, winning_team };
    broadcast_with_repeat(MESH_GAME_END, payload, 2, repeat_count);
}

void mesh_broadcast_scoreboard(uint8_t num_teams,
                               const uint8_t *team_ids, const uint16_t *team_kills)
{
    uint8_t payload[32];
    uint8_t idx = 0;
    payload[idx++] = num_teams;
    for (int i = 0; i < num_teams && idx + 3 <= sizeof(payload); i++) {
        payload[idx++] = team_ids[i];
        sys_put_le16(team_kills[i], &payload[idx]); idx += 2;
    }

    uint8_t buf[256];
    uint16_t len = build_mesh_packet(buf, sizeof(buf), MESH_SCOREBOARD, payload, idx);
    if (len > 0) {
        do_coded_broadcast(buf, len);
    }
}

void mesh_broadcast_player_respawn(uint8_t player_id, uint8_t repeat_count)
{
    uint8_t payload[1] = { player_id };
    broadcast_with_repeat(MESH_PLAYER_RESPAWN, payload, 1, repeat_count);
}

void mesh_process_received(const uint8_t *data, uint16_t len, int8_t rssi)
{
    if (len < MESH_HEADER_SIZE) {
        return;
    }

    struct mesh_header hdr;
    hdr.mesh_type   = data[0];
    hdr.origin_id   = data[1];
    hdr.seq_num     = sys_get_le16(&data[2]);
    hdr.ttl         = data[4];
    hdr.payload_len = data[5];

    if (hdr.origin_id == local_player_id) {
        return;
    }

    if (dedup_check_and_insert(hdr.origin_id, hdr.seq_num)) {
        return;
    }

    LOG_INF("Mesh RX: type=0x%02x from=%d seq=%d ttl=%d rssi=%d",
            hdr.mesh_type, hdr.origin_id, hdr.seq_num, hdr.ttl, rssi);

    /* Privacy filter: only relay PLAYER_STATE from same team */
    bool should_relay = true;
    bool should_forward = true;

    if (hdr.mesh_type == MESH_PLAYER_STATE && hdr.payload_len >= 2) {
        uint8_t msg_team_id = data[MESH_HEADER_SIZE + 1];
        if (msg_team_id != local_team_id) {
            should_relay = false;
            should_forward = false;
        }
    }

    /* Joiner self-start: a peer's GAME_START carries the full game config.
     * Apply it locally so this emitter enters its active game state without a
     * phone round-trip. Fires once per unique frame (dedup-gated above). The
     * normal relay below still propagates the frame to further-hop peers. */
    if (hdr.mesh_type == MESH_GAME_START && game_start_cb &&
        MESH_HEADER_SIZE + hdr.payload_len <= len) {
        game_start_cb(&data[MESH_HEADER_SIZE], hdr.payload_len);
    }

    if (should_forward) {
        forward_to_phone(data, len);
    }

    if (should_relay && hdr.ttl > 0) {
        relay_message(data, len);
    }
}

/* Called during init to create the Coded PHY advertising set */
int mesh_create_coded_adv_set(void)
{
    struct bt_le_adv_param adv_param = {
        .id = BT_ID_DEFAULT,
        .sid = 1,
        .secondary_max_skip = 0,
        .options = BT_LE_ADV_OPT_EXT_ADV | BT_LE_ADV_OPT_CODED,
        .interval_min = BT_GAP_ADV_FAST_INT_MIN_2,
        .interval_max = BT_GAP_ADV_FAST_INT_MAX_2,
        .peer = NULL,
    };

    int err = bt_le_ext_adv_create(&adv_param, NULL, &coded_adv_set);
    if (err) {
        LOG_ERR("Coded PHY adv set create failed (err %d)", err);
    }
    return err;
}
```

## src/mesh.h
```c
#ifndef MESH_H
#define MESH_H

#include "protocol.h"
#include <zephyr/bluetooth/bluetooth.h>
#include <zephyr/bluetooth/conn.h>
#include <stdint.h>

void mesh_init(void);
void mesh_set_identity(uint8_t player_id, uint8_t team_id);
void mesh_set_phone_conn(struct bt_conn *conn);
void mesh_start_scanner(void);
void mesh_stop_scanner(void);

/* Raw broadcast (for CMD_BROADCAST_CODED_PHY from phone) */
void mesh_broadcast_raw(const uint8_t *data, uint16_t len);

/* Typed broadcasts */
void mesh_broadcast_lobby_announce(uint32_t lobby_code, uint8_t game_mode,
                                   const char *host_name, uint8_t player_count);
void mesh_broadcast_lobby_join(uint32_t lobby_code, uint8_t player_id,
                               const char *username);
/* Roster sync from host. roster bytes = lobby_code[4] + N×[pid,tid,nameLen,name],
 * built phone-side and wrapped here in a MESH_LOBBY_STATE frame. */
void mesh_broadcast_lobby_state(const uint8_t *roster, uint16_t roster_len,
                                uint8_t repeat_count);
void mesh_broadcast_game_start(const uint8_t *config_data, uint16_t config_len,
                               uint8_t repeat_count);

/* Fired from mesh_process_received when a peer's MESH_GAME_START arrives
 * (non-origin, post-dedup) so the joiner's emitter can self-start the game
 * locally. cfg points at the raw game-config bytes (same layout as the
 * CMD_BROADCAST_GAME_CFG payload). */
typedef void (*mesh_game_start_cb_t)(const uint8_t *cfg, uint16_t len);
void mesh_set_game_start_cb(mesh_game_start_cb_t cb);
void mesh_broadcast_player_state(uint8_t player_id, uint8_t team_id,
                                 int32_t lat, int32_t lon,
                                 uint8_t health, uint8_t ammo_pct,
                                 uint8_t alive, uint16_t kills, uint16_t deaths);
void mesh_broadcast_hit_event(uint8_t shooter_id, uint8_t target_id,
                              uint8_t damage, uint8_t remaining_health,
                              uint8_t hit_zone);
void mesh_broadcast_player_death(uint8_t player_id, uint8_t killer_id,
                                 uint16_t final_kills, uint16_t final_deaths,
                                 uint8_t repeat_count);
void mesh_broadcast_game_end(uint8_t reason, uint8_t winning_team,
                             uint8_t repeat_count);
void mesh_broadcast_scoreboard(uint8_t num_teams,
                               const uint8_t *team_ids, const uint16_t *team_kills);
void mesh_broadcast_player_respawn(uint8_t player_id, uint8_t repeat_count);

/* Called from scan callback with received Coded PHY data */
void mesh_process_received(const uint8_t *data, uint16_t len, int8_t rssi);

/* Create the Coded PHY extended advertising set (call once after bt_enable) */
int mesh_create_coded_adv_set(void);

#endif
```
